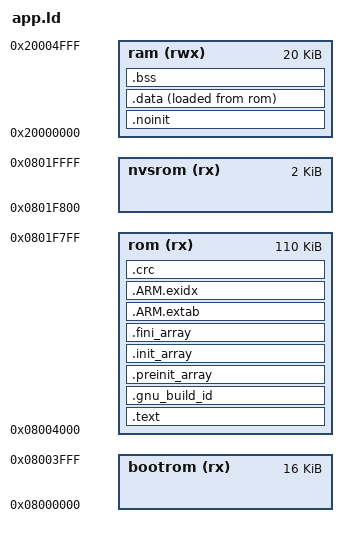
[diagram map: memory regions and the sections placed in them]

MEMORY
{
    bootrom  (rx)  : ORIGIN = 0x08000000, LENGTH = 16K
    rom (rx) : ORIGIN = 0x8004000, LENGTH = 110k
    nvsrom (rx) : ORIGIN = 0x0801F800, LENGTH = 2K
    ram (rwx) : ORIGIN = 0x20000000, LENGTH = 20K
}

__bootrom_start__ = ORIGIN(bootrom);
__bootrom_size__ = LENGTH(bootrom);
__approm_start__ = ORIGIN(rom);
__approm_size__ = LENGTH(rom);
__nvsrom_start__ = ORIGIN(nvsrom);
__nvsrom_size__ = LENGTH(nvsrom);


/* Enforce emmition of the vector table. */
EXTERN (vector_table)

/* Define the entry point of the output file. */
ENTRY(reset_handler)

/* Define sections. */
SECTIONS
{
	.text : {
		KEEP (*(.image_header))
		. = ALIGN(128);
		*(.vectors)	/* Vector table */
		*(.text*)	/* Program code */
		. = ALIGN(4);
		*(.rodata*)	/* Read-only data */
		. = ALIGN(4);
	} >rom

	.gnu_build_id : {
		PROVIDE(note_build_id = .);
		*(.note.gnu.build-id)
	} >rom

	/* C++ Static constructors/destructors, also used for __attribute__
	 * ((constructor)) and the likes */
	.preinit_array : {
		. = ALIGN(4);
		__preinit_array_start = .;
		KEEP (*(.preinit_array))
		__preinit_array_end = .;
	} >rom
	.init_array : {
		. = ALIGN(4);
		__init_array_start = .;
		KEEP (*(SORT(.init_array.*)))
		KEEP (*(.init_array))
		__init_array_end = .;
	} >rom
	.fini_array : {
		. = ALIGN(4);
		__fini_array_start = .;
		KEEP (*(.fini_array))
		KEEP (*(SORT(.fini_array.*)))
		__fini_array_end = .;
	} >rom

	/*
	 * Another section used by C++ stuff, appears when using newlib with
	 * 64bit (long long) printf support
	 */
	.ARM.extab : {
		*(.ARM.extab*)
	} >rom
	.ARM.exidx : {
		__exidx_start = .;
		*(.ARM.exidx*)
		__exidx_end = .;
	} >rom

	. = ALIGN(4);
	_etext = .;

	/* ram, but not cleared on reset, eg boot/app comms */
	.noinit (NOLOAD) : {
		*(.noinit*)
	} >ram
	. = ALIGN(4);

	.data : {
		_data = .;
		*(.data*)	/* Read-write initialized data */
		*(.ramtext*)    /* "text" functions to run in ram */
		. = ALIGN(4);
		_edata = .;
	} >ram AT >rom
	_data_loadaddr = LOADADDR(.data);

	.crc : {

		KEEP (*(.crc))
	} >rom

	.bss : {
		*(.bss*)	/* Read-write zero initialized data */
		*(COMMON)
		. = ALIGN(4);
		_ebss = .;
	} >ram

	/*
	 * The .eh_frame section appears to be used for C++ exception handling.
	 * You may need to fix this if you're using C++.
	 */
	/DISCARD/ : { *(.eh_frame) }



	. = ALIGN(4);
	end = .;
}

PROVIDE(_stack = ORIGIN(ram) + LENGTH(ram));

